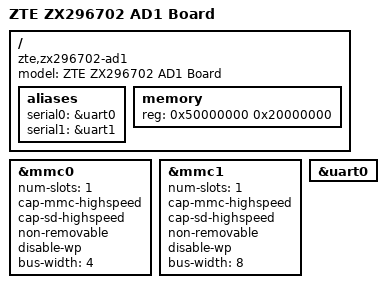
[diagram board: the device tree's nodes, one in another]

/dts-v1/;

#include "zx296702.dtsi"

/ {
	model = "ZTE ZX296702 AD1 Board";
	compatible = "zte,zx296702-ad1", "zte,zx296702";

	aliases {
		serial0 = &uart0;
		serial1 = &uart1;
	};

	memory {
		reg = <0x50000000 0x20000000>;
	};
};

&mmc0 {
	num-slots = <1>;
	cap-mmc-highspeed;
	cap-sd-highspeed;
	non-removable;
	disable-wp;
	bus-width = <4>;
	status = "okay";
};

&mmc1 {
	num-slots = <1>;
	cap-mmc-highspeed;
	cap-sd-highspeed;
	non-removable;
	disable-wp;
	bus-width = <8>;
	status = "okay";
};

&uart0 {
	status = "okay";
};
